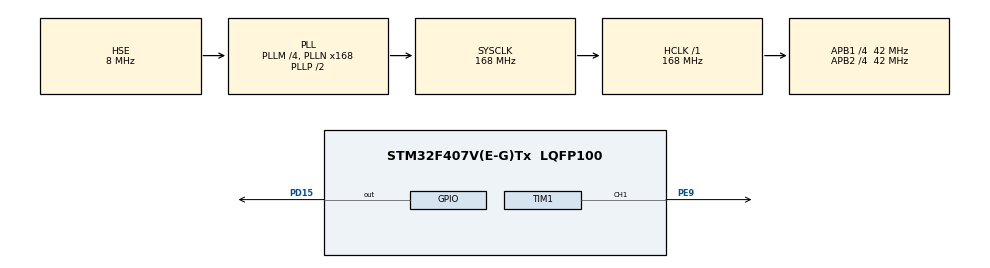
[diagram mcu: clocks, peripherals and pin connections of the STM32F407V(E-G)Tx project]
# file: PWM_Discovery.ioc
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Mcu.Family=STM32F4
Mcu.Name=STM32F407V(E-G)Tx
Mcu.Package=LQFP100
NVIC.PriorityGroup=NVIC_PRIORITYGROUP_4
PD15.Signal=GPIO_Output
PE9.Signal=S_TIM1_CH1
PH0-OSC_IN.Mode=HSE-External-Clock-Source
PH0-OSC_IN.Signal=RCC_OSC_IN
PH1-OSC_OUT.Mode=HSE-External-Clock-Source
PH1-OSC_OUT.Signal=RCC_OSC_OUT
ProjectManager.HeapSize=0x200
ProjectManager.StackSize=0x400
ProjectManager.TargetToolchain=Other Toolchains (GPDSC)
RCC.48MHZClocksFreq_Value=84000000
RCC.AHBFreq_Value=168000000
RCC.APB1CLKDivider=RCC_HCLK_DIV4
RCC.APB1Freq_Value=42000000
RCC.APB1TimFreq_Value=84000000
RCC.APB2CLKDivider=RCC_HCLK_DIV4
RCC.APB2Freq_Value=42000000
RCC.APB2TimFreq_Value=84000000
RCC.CortexFreq_Value=168000000
RCC.HCLKFreq_Value=168000000
RCC.HSE_VALUE=8000000
RCC.HSI_VALUE=16000000
RCC.LSE_VALUE=32768
RCC.PLLM=4
RCC.PLLN=168
RCC.PLLSourceVirtual=RCC_PLLSOURCE_HSE
RCC.SYSCLKFreq_VALUE=168000000
RCC.SYSCLKSource=RCC_SYSCLKSOURCE_PLLCLK
RCC.VCOOutputFreq_Value=336000000
SH.S_TIM1_CH1.0=TIM1_CH1,PWM Generation1 CH1
TIM1.Channel-PWM\ Generation1\ CH1=TIM_CHANNEL_1
TIM1.Period=56022
TIM1.Prescaler=0
TIM1.Pulse-PWM\ Generation1\ CH1=28011
VP_TIM1_VS_ClockSourceINT.Mode=Internal
board=custom

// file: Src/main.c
/* USER CODE BEGIN Header */
/**
  ******************************************************************************
  * @file           : main.c
  * @brief          : Main program body
  ******************************************************************************
  ** This notice applies to any and all portions of this file
  * that are not between comment pairs USER CODE BEGIN and
  * USER CODE END. Other portions of this file, whether
  * inserted by the user or by software development tools
  * are owned by their respective copyright owners.
  *
  * COPYRIGHT(c) 2020 STMicroelectronics
  *
  * Redistribution and use in source and binary forms, with or without modification,
  * are permitted provided that the following conditions are met:
  *   1. Redistributions of source code must retain the above copyright notice,
  *      this list of conditions and the following disclaimer.
  *   2. Redistributions in binary form must reproduce the above copyright notice,
  *      this list of conditions and the following disclaimer in the documentation
  *      and/or other materials provided with the distribution.
  *   3. Neither the name of STMicroelectronics nor the names of its contributors
  *      may be used to endorse or promote products derived from this software
  *      without specific prior written permission.
  *
  * THIS SOFTWARE IS PROVIDED BY THE COPYRIGHT HOLDERS AND CONTRIBUTORS "AS IS"
  * AND ANY EXPRESS OR IMPLIED WARRANTIES, INCLUDING, BUT NOT LIMITED TO, THE
  * IMPLIED WARRANTIES OF MERCHANTABILITY AND FITNESS FOR A PARTICULAR PURPOSE ARE
  * DISCLAIMED. IN NO EVENT SHALL THE COPYRIGHT HOLDER OR CONTRIBUTORS BE LIABLE
  * FOR ANY DIRECT, INDIRECT, INCIDENTAL, SPECIAL, EXEMPLARY, OR CONSEQUENTIAL
  * DAMAGES (INCLUDING, BUT NOT LIMITED TO, PROCUREMENT OF SUBSTITUTE GOODS OR
  * SERVICES; LOSS OF USE, DATA, OR PROFITS; OR BUSINESS INTERRUPTION) HOWEVER
  * CAUSED AND ON ANY THEORY OF LIABILITY, WHETHER IN CONTRACT, STRICT LIABILITY,
  * OR TORT (INCLUDING NEGLIGENCE OR OTHERWISE) ARISING IN ANY WAY OUT OF THE USE
  * OF THIS SOFTWARE, EVEN IF ADVISED OF THE POSSIBILITY OF SUCH DAMAGE.
  *
  ******************************************************************************
  */
/* USER CODE END Header */

#include "main.h"

TIM_HandleTypeDef htim1;

void SystemClock_Config(void);
static void MX_GPIO_Init(void);
static void MX_TIM1_Init(void);

int main(void)
{

  /* MCU Configuration--------------------------------------------------------*/

  /* Reset of all peripherals, Initializes the Flash interface and the Systick. */
  HAL_Init();

  /* Configure the system clock */
  SystemClock_Config();

  /* Initialize all configured peripherals */
  MX_GPIO_Init();
  MX_TIM1_Init();
  /* USER CODE BEGIN 2 */
  HAL_TIM_PWM_Start(&htim1,TIM_CHANNEL_1);
  /* USER CODE END 2 */

  /* Infinite loop */
  /* USER CODE BEGIN WHILE */
  while (1)
  {
    HAL_GPIO_TogglePin(GPIOD, GPIO_PIN_15);
    TIM1->CCR1 = 56022/2;
    HAL_Delay(150);
    TIM1->CCR1 = 56022/4;
    HAL_Delay(150);
    TIM1->CCR1 = 56022/8;
    HAL_Delay(150);

    /* USER CODE END WHILE */

  }
}

void SystemClock_Config(void)
{
  RCC_OscInitTypeDef RCC_OscInitStruct = {0};
  RCC_ClkInitTypeDef RCC_ClkInitStruct = {0};

  /**Configure the main internal regulator output voltage
  */
  __HAL_RCC_PWR_CLK_ENABLE();
  __HAL_PWR_VOLTAGESCALING_CONFIG(PWR_REGULATOR_VOLTAGE_SCALE1);
  /**Initializes the CPU, AHB and APB busses clocks
  */
  RCC_OscInitStruct.OscillatorType = RCC_OSCILLATORTYPE_HSE;
  RCC_OscInitStruct.HSEState = RCC_HSE_BYPASS;
  RCC_OscInitStruct.PLL.PLLState = RCC_PLL_ON;
  RCC_OscInitStruct.PLL.PLLSource = RCC_PLLSOURCE_HSE;
  RCC_OscInitStruct.PLL.PLLM = 4;
  RCC_OscInitStruct.PLL.PLLN = 168;
  RCC_OscInitStruct.PLL.PLLP = RCC_PLLP_DIV2;
  RCC_OscInitStruct.PLL.PLLQ = 4;
  if (HAL_RCC_OscConfig(&RCC_OscInitStruct) != HAL_OK)
  {
    Error_Handler();
  }
  /**Initializes the CPU, AHB and APB busses clocks
  */
  RCC_ClkInitStruct.ClockType = RCC_CLOCKTYPE_HCLK|RCC_CLOCKTYPE_SYSCLK
                              |RCC_CLOCKTYPE_PCLK1|RCC_CLOCKTYPE_PCLK2;
  RCC_ClkInitStruct.SYSCLKSource = RCC_SYSCLKSOURCE_PLLCLK;
  RCC_ClkInitStruct.AHBCLKDivider = RCC_SYSCLK_DIV1;
  RCC_ClkInitStruct.APB1CLKDivider = RCC_HCLK_DIV4;
  RCC_ClkInitStruct.APB2CLKDivider = RCC_HCLK_DIV4;

  if (HAL_RCC_ClockConfig(&RCC_ClkInitStruct, FLASH_LATENCY_5) != HAL_OK)
  {
    Error_Handler();
  }
}

static void MX_TIM1_Init(void)
{

  TIM_ClockConfigTypeDef sClockSourceConfig = {0};
  TIM_MasterConfigTypeDef sMasterConfig = {0};
  TIM_OC_InitTypeDef sConfigOC = {0};
  TIM_BreakDeadTimeConfigTypeDef sBreakDeadTimeConfig = {0};

  htim1.Instance = TIM1;
  htim1.Init.Prescaler = 0;
  htim1.Init.CounterMode = TIM_COUNTERMODE_UP;
  htim1.Init.Period = 56022;
  htim1.Init.ClockDivision = TIM_CLOCKDIVISION_DIV1;
  htim1.Init.RepetitionCounter = 0;
  if (HAL_TIM_Base_Init(&htim1) != HAL_OK)
  {
    Error_Handler();
  }
  sClockSourceConfig.ClockSource = TIM_CLOCKSOURCE_INTERNAL;
  if (HAL_TIM_ConfigClockSource(&htim1, &sClockSourceConfig) != HAL_OK)
  {
    Error_Handler();
  }
  if (HAL_TIM_PWM_Init(&htim1) != HAL_OK)
  {
    Error_Handler();
  }
  sMasterConfig.MasterOutputTrigger = TIM_TRGO_RESET;
  sMasterConfig.MasterSlaveMode = TIM_MASTERSLAVEMODE_DISABLE;
  if (HAL_TIMEx_MasterConfigSynchronization(&htim1, &sMasterConfig) != HAL_OK)
  {
    Error_Handler();
  }
  sConfigOC.OCMode = TIM_OCMODE_PWM1;
  sConfigOC.Pulse = 28011;
  sConfigOC.OCPolarity = TIM_OCPOLARITY_HIGH;
  sConfigOC.OCNPolarity = TIM_OCNPOLARITY_HIGH;
  sConfigOC.OCFastMode = TIM_OCFAST_DISABLE;
  sConfigOC.OCIdleState = TIM_OCIDLESTATE_RESET;
  sConfigOC.OCNIdleState = TIM_OCNIDLESTATE_RESET;
  if (HAL_TIM_PWM_ConfigChannel(&htim1, &sConfigOC, TIM_CHANNEL_1) != HAL_OK)
  {
    Error_Handler();
  }
  sBreakDeadTimeConfig.OffStateRunMode = TIM_OSSR_DISABLE;
  sBreakDeadTimeConfig.OffStateIDLEMode = TIM_OSSI_DISABLE;
  sBreakDeadTimeConfig.LockLevel = TIM_LOCKLEVEL_OFF;
  sBreakDeadTimeConfig.DeadTime = 0;
  sBreakDeadTimeConfig.BreakState = TIM_BREAK_DISABLE;
  sBreakDeadTimeConfig.BreakPolarity = TIM_BREAKPOLARITY_HIGH;
  sBreakDeadTimeConfig.AutomaticOutput = TIM_AUTOMATICOUTPUT_DISABLE;
  if (HAL_TIMEx_ConfigBreakDeadTime(&htim1, &sBreakDeadTimeConfig) != HAL_OK)
  {
    Error_Handler();
  }
  HAL_TIM_MspPostInit(&htim1);

}

static void MX_GPIO_Init(void)
{
  GPIO_InitTypeDef GPIO_InitStruct = {0};

  /* GPIO Ports Clock Enable */
  __HAL_RCC_GPIOH_CLK_ENABLE();
  __HAL_RCC_GPIOE_CLK_ENABLE();
  __HAL_RCC_GPIOD_CLK_ENABLE();

  /*Configure GPIO pin Output Level */
  HAL_GPIO_WritePin(GPIOD, GPIO_PIN_15, GPIO_PIN_RESET);

  /*Configure GPIO pin : PD15 */
  GPIO_InitStruct.Pin = GPIO_PIN_15;
  GPIO_InitStruct.Mode = GPIO_MODE_OUTPUT_PP;
  GPIO_InitStruct.Pull = GPIO_NOPULL;
  GPIO_InitStruct.Speed = GPIO_SPEED_FREQ_LOW;
  HAL_GPIO_Init(GPIOD, &GPIO_InitStruct);

}

void Error_Handler(void)
{
}

/************************ (C) COPYRIGHT STMicroelectronics *****END OF FILE****/
